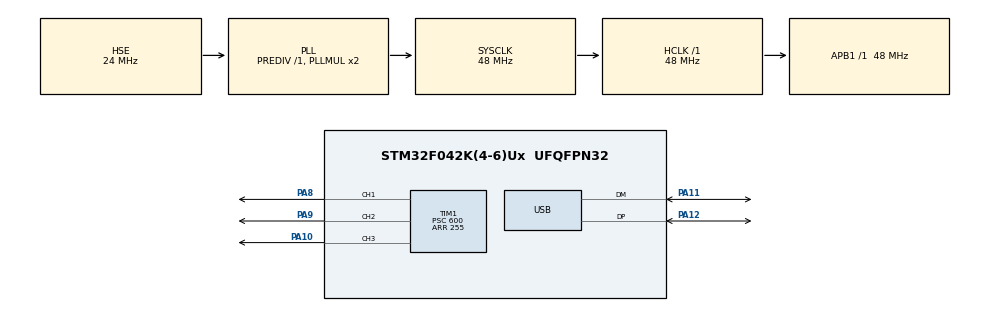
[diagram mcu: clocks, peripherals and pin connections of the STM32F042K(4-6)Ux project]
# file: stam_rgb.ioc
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Mcu.Family=STM32F0
Mcu.Name=STM32F042K(4-6)Ux
Mcu.Package=UFQFPN32
PA10.Signal=S_TIM1_CH3
PA11.Mode=Device
PA11.Signal=USB_DM
PA12.Mode=Device
PA12.Signal=USB_DP
PA13.Mode=Serial_Wire
PA13.Signal=SYS_SWDIO
PA14.Mode=Serial_Wire
PA14.Signal=SYS_SWCLK
PA8.Signal=S_TIM1_CH1
PA9.Signal=S_TIM1_CH2
PF0-OSC_IN.Mode=HSE-External-Oscillator
PF0-OSC_IN.Signal=RCC_OSC_IN
PF1-OSC_OUT.Mode=HSE-External-Oscillator
PF1-OSC_OUT.Signal=RCC_OSC_OUT
ProjectManager.HeapSize=0x200
ProjectManager.StackSize=0x400
ProjectManager.TargetToolchain=TrueSTUDIO
RCC.AHBFreq_Value=48000000
RCC.APB1Freq_Value=48000000
RCC.APB1TimFreq_Value=48000000
RCC.HCLKFreq_Value=48000000
RCC.HSE_VALUE=24000000
RCC.SYSCLKFreq_VALUE=48000000
RCC.SYSCLKSource=RCC_SYSCLKSOURCE_PLLCLK
RCC.USBClockSelection=RCC_USBCLKSOURCE_PLL
SH.S_TIM1_CH1.0=TIM1_CH1,PWM Generation1 CH1
SH.S_TIM1_CH2.0=TIM1_CH2,PWM Generation2 CH2
SH.S_TIM1_CH3.0=TIM1_CH3,PWM Generation3 CH3
TIM1.AutoReloadPreload=TIM_AUTORELOAD_PRELOAD_ENABLE
TIM1.Channel-PWM\ Generation1\ CH1=TIM_CHANNEL_1
TIM1.Channel-PWM\ Generation2\ CH2=TIM_CHANNEL_2
TIM1.Channel-PWM\ Generation3\ CH3=TIM_CHANNEL_3
TIM1.OCIdleState_1=TIM_OCIDLESTATE_SET
TIM1.OCIdleState_2=TIM_OCIDLESTATE_SET
TIM1.OCIdleState_3=TIM_OCIDLESTATE_SET
TIM1.OCPolarity_1=TIM_OCPOLARITY_HIGH
TIM1.Period=255
TIM1.Prescaler=600
TIM1.Pulse-PWM\ Generation1\ CH1=200
TIM1.Pulse-PWM\ Generation2\ CH2=200
TIM1.Pulse-PWM\ Generation3\ CH3=200
VP_TIM1_VS_ClockSourceINT.Mode=Internal
board=custom

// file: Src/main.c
/* USER CODE BEGIN Header */
/**
  ******************************************************************************
  * @file           : main.c
  * @brief          : Main program body
  ******************************************************************************
  ** This notice applies to any and all portions of this file
  * that are not between comment pairs USER CODE BEGIN and
  * USER CODE END. Other portions of this file, whether
  * inserted by the user or by software development tools
  * are owned by their respective copyright owners.
  *
  * COPYRIGHT(c) 2019 STMicroelectronics
  *
  * Redistribution and use in source and binary forms, with or without modification,
  * are permitted provided that the following conditions are met:
  *   1. Redistributions of source code must retain the above copyright notice,
  *      this list of conditions and the following disclaimer.
  *   2. Redistributions in binary form must reproduce the above copyright notice,
  *      this list of conditions and the following disclaimer in the documentation
  *      and/or other materials provided with the distribution.
  *   3. Neither the name of STMicroelectronics nor the names of its contributors
  *      may be used to endorse or promote products derived from this software
  *      without specific prior written permission.
  *
  * THIS SOFTWARE IS PROVIDED BY THE COPYRIGHT HOLDERS AND CONTRIBUTORS "AS IS"
  * AND ANY EXPRESS OR IMPLIED WARRANTIES, INCLUDING, BUT NOT LIMITED TO, THE
  * IMPLIED WARRANTIES OF MERCHANTABILITY AND FITNESS FOR A PARTICULAR PURPOSE ARE
  * DISCLAIMED. IN NO EVENT SHALL THE COPYRIGHT HOLDER OR CONTRIBUTORS BE LIABLE
  * FOR ANY DIRECT, INDIRECT, INCIDENTAL, SPECIAL, EXEMPLARY, OR CONSEQUENTIAL
  * DAMAGES (INCLUDING, BUT NOT LIMITED TO, PROCUREMENT OF SUBSTITUTE GOODS OR
  * SERVICES; LOSS OF USE, DATA, OR PROFITS; OR BUSINESS INTERRUPTION) HOWEVER
  * CAUSED AND ON ANY THEORY OF LIABILITY, WHETHER IN CONTRACT, STRICT LIABILITY,
  * OR TORT (INCLUDING NEGLIGENCE OR OTHERWISE) ARISING IN ANY WAY OUT OF THE USE
  * OF THIS SOFTWARE, EVEN IF ADVISED OF THE POSSIBILITY OF SUCH DAMAGE.
  *
  ******************************************************************************
  */
/* USER CODE END Header */

#include "main.h"

/* USER CODE BEGIN Includes */
#include "usb.h"
/* USER CODE END Includes */

/* USER CODE BEGIN PM */
#define USB_PRINT(x) usb_tx_post(x,sizeof(x))

/* USER CODE END PM */

TIM_HandleTypeDef htim1;

PCD_HandleTypeDef hpcd_USB_FS;

void SystemClock_Config(void);
static void MX_GPIO_Init(void);
static void MX_TIM1_Init(void);
static void MX_USB_PCD_Init(void);

/* USER CODE BEGIN 0 */
extern usbd_device* udev;

/* USER CODE END 0 */

int main(void)
{

  /* MCU Configuration--------------------------------------------------------*/

  /* Reset of all peripherals, Initializes the Flash interface and the Systick. */
  HAL_Init();

  /* Configure the system clock */
  SystemClock_Config();

  /* Initialize all configured peripherals */
  MX_GPIO_Init();
  MX_TIM1_Init();
  MX_USB_PCD_Init();
  /* USER CODE BEGIN 2 */
  cdc_init_usbd();
  usbd_enable(&udev, true);
  usbd_connect(&udev, true);

  HAL_NVIC_EnableIRQ(USB_IRQn);

  HAL_TIM_Base_Start(&htim1);
  HAL_TIM_PWM_Start(&htim1,TIM_CHANNEL_1);
  HAL_TIM_PWM_Start(&htim1,TIM_CHANNEL_2);
  HAL_TIM_PWM_Start(&htim1,TIM_CHANNEL_3);

  /* USER CODE END 2 */

  /* Infinite loop */
  while (1)
  {

    /* USER CODE BEGIN 3 */
	  //USB_PRINT("about to init lcd.\n\r");
	  HAL_Delay(200);
  }
  /* USER CODE END 3 */
}

void SystemClock_Config(void)
{
  RCC_OscInitTypeDef RCC_OscInitStruct = {0};
  RCC_ClkInitTypeDef RCC_ClkInitStruct = {0};
  RCC_PeriphCLKInitTypeDef PeriphClkInit = {0};

  /**Initializes the CPU, AHB and APB busses clocks
  */
  RCC_OscInitStruct.OscillatorType = RCC_OSCILLATORTYPE_HSE;
  RCC_OscInitStruct.HSEState = RCC_HSE_ON;
  RCC_OscInitStruct.PLL.PLLState = RCC_PLL_ON;
  RCC_OscInitStruct.PLL.PLLSource = RCC_PLLSOURCE_HSE;
  RCC_OscInitStruct.PLL.PLLMUL = RCC_PLL_MUL2;
  RCC_OscInitStruct.PLL.PREDIV = RCC_PREDIV_DIV1;
  if (HAL_RCC_OscConfig(&RCC_OscInitStruct) != HAL_OK)
  {
    Error_Handler();
  }
  /**Initializes the CPU, AHB and APB busses clocks
  */
  RCC_ClkInitStruct.ClockType = RCC_CLOCKTYPE_HCLK|RCC_CLOCKTYPE_SYSCLK
                              |RCC_CLOCKTYPE_PCLK1;
  RCC_ClkInitStruct.SYSCLKSource = RCC_SYSCLKSOURCE_PLLCLK;
  RCC_ClkInitStruct.AHBCLKDivider = RCC_SYSCLK_DIV1;
  RCC_ClkInitStruct.APB1CLKDivider = RCC_HCLK_DIV1;

  if (HAL_RCC_ClockConfig(&RCC_ClkInitStruct, FLASH_LATENCY_1) != HAL_OK)
  {
    Error_Handler();
  }
  PeriphClkInit.PeriphClockSelection = RCC_PERIPHCLK_USB;
  PeriphClkInit.UsbClockSelection = RCC_USBCLKSOURCE_PLL;

  if (HAL_RCCEx_PeriphCLKConfig(&PeriphClkInit) != HAL_OK)
  {
    Error_Handler();
  }
}

static void MX_TIM1_Init(void)
{

  TIM_ClockConfigTypeDef sClockSourceConfig = {0};
  TIM_MasterConfigTypeDef sMasterConfig = {0};
  TIM_OC_InitTypeDef sConfigOC = {0};
  TIM_BreakDeadTimeConfigTypeDef sBreakDeadTimeConfig = {0};

  htim1.Instance = TIM1;
  htim1.Init.Prescaler = 600;
  htim1.Init.CounterMode = TIM_COUNTERMODE_UP;
  htim1.Init.Period = 255;
  htim1.Init.ClockDivision = TIM_CLOCKDIVISION_DIV1;
  htim1.Init.RepetitionCounter = 0;
  htim1.Init.AutoReloadPreload = TIM_AUTORELOAD_PRELOAD_ENABLE;
  if (HAL_TIM_Base_Init(&htim1) != HAL_OK)
  {
    Error_Handler();
  }
  sClockSourceConfig.ClockSource = TIM_CLOCKSOURCE_INTERNAL;
  if (HAL_TIM_ConfigClockSource(&htim1, &sClockSourceConfig) != HAL_OK)
  {
    Error_Handler();
  }
  if (HAL_TIM_PWM_Init(&htim1) != HAL_OK)
  {
    Error_Handler();
  }
  sMasterConfig.MasterOutputTrigger = TIM_TRGO_RESET;
  sMasterConfig.MasterSlaveMode = TIM_MASTERSLAVEMODE_DISABLE;
  if (HAL_TIMEx_MasterConfigSynchronization(&htim1, &sMasterConfig) != HAL_OK)
  {
    Error_Handler();
  }
  sConfigOC.OCMode = TIM_OCMODE_PWM1;
  sConfigOC.Pulse = 200;
  sConfigOC.OCPolarity = TIM_OCPOLARITY_HIGH;
  sConfigOC.OCNPolarity = TIM_OCNPOLARITY_HIGH;
  sConfigOC.OCFastMode = TIM_OCFAST_DISABLE;
  sConfigOC.OCIdleState = TIM_OCIDLESTATE_SET;
  sConfigOC.OCNIdleState = TIM_OCNIDLESTATE_RESET;
  if (HAL_TIM_PWM_ConfigChannel(&htim1, &sConfigOC, TIM_CHANNEL_1) != HAL_OK)
  {
    Error_Handler();
  }
  if (HAL_TIM_PWM_ConfigChannel(&htim1, &sConfigOC, TIM_CHANNEL_2) != HAL_OK)
  {
    Error_Handler();
  }
  if (HAL_TIM_PWM_ConfigChannel(&htim1, &sConfigOC, TIM_CHANNEL_3) != HAL_OK)
  {
    Error_Handler();
  }
  sBreakDeadTimeConfig.OffStateRunMode = TIM_OSSR_DISABLE;
  sBreakDeadTimeConfig.OffStateIDLEMode = TIM_OSSI_DISABLE;
  sBreakDeadTimeConfig.LockLevel = TIM_LOCKLEVEL_OFF;
  sBreakDeadTimeConfig.DeadTime = 0;
  sBreakDeadTimeConfig.BreakState = TIM_BREAK_DISABLE;
  sBreakDeadTimeConfig.BreakPolarity = TIM_BREAKPOLARITY_HIGH;
  sBreakDeadTimeConfig.AutomaticOutput = TIM_AUTOMATICOUTPUT_DISABLE;
  if (HAL_TIMEx_ConfigBreakDeadTime(&htim1, &sBreakDeadTimeConfig) != HAL_OK)
  {
    Error_Handler();
  }
  HAL_TIM_MspPostInit(&htim1);

}

static void MX_USB_PCD_Init(void)
{

  hpcd_USB_FS.Instance = USB;
  hpcd_USB_FS.Init.dev_endpoints = 8;
  hpcd_USB_FS.Init.speed = PCD_SPEED_FULL;
  hpcd_USB_FS.Init.ep0_mps = DEP0CTL_MPS_64;
  hpcd_USB_FS.Init.phy_itface = PCD_PHY_EMBEDDED;
  hpcd_USB_FS.Init.low_power_enable = DISABLE;
  hpcd_USB_FS.Init.lpm_enable = DISABLE;
  hpcd_USB_FS.Init.battery_charging_enable = DISABLE;
  if (HAL_PCD_Init(&hpcd_USB_FS) != HAL_OK)
  {
    Error_Handler();
  }

}

static void MX_GPIO_Init(void)
{

  /* GPIO Ports Clock Enable */
  __HAL_RCC_GPIOF_CLK_ENABLE();
  __HAL_RCC_GPIOA_CLK_ENABLE();

}

void Error_Handler(void)
{
}

/************************ (C) COPYRIGHT STMicroelectronics *****END OF FILE****/
